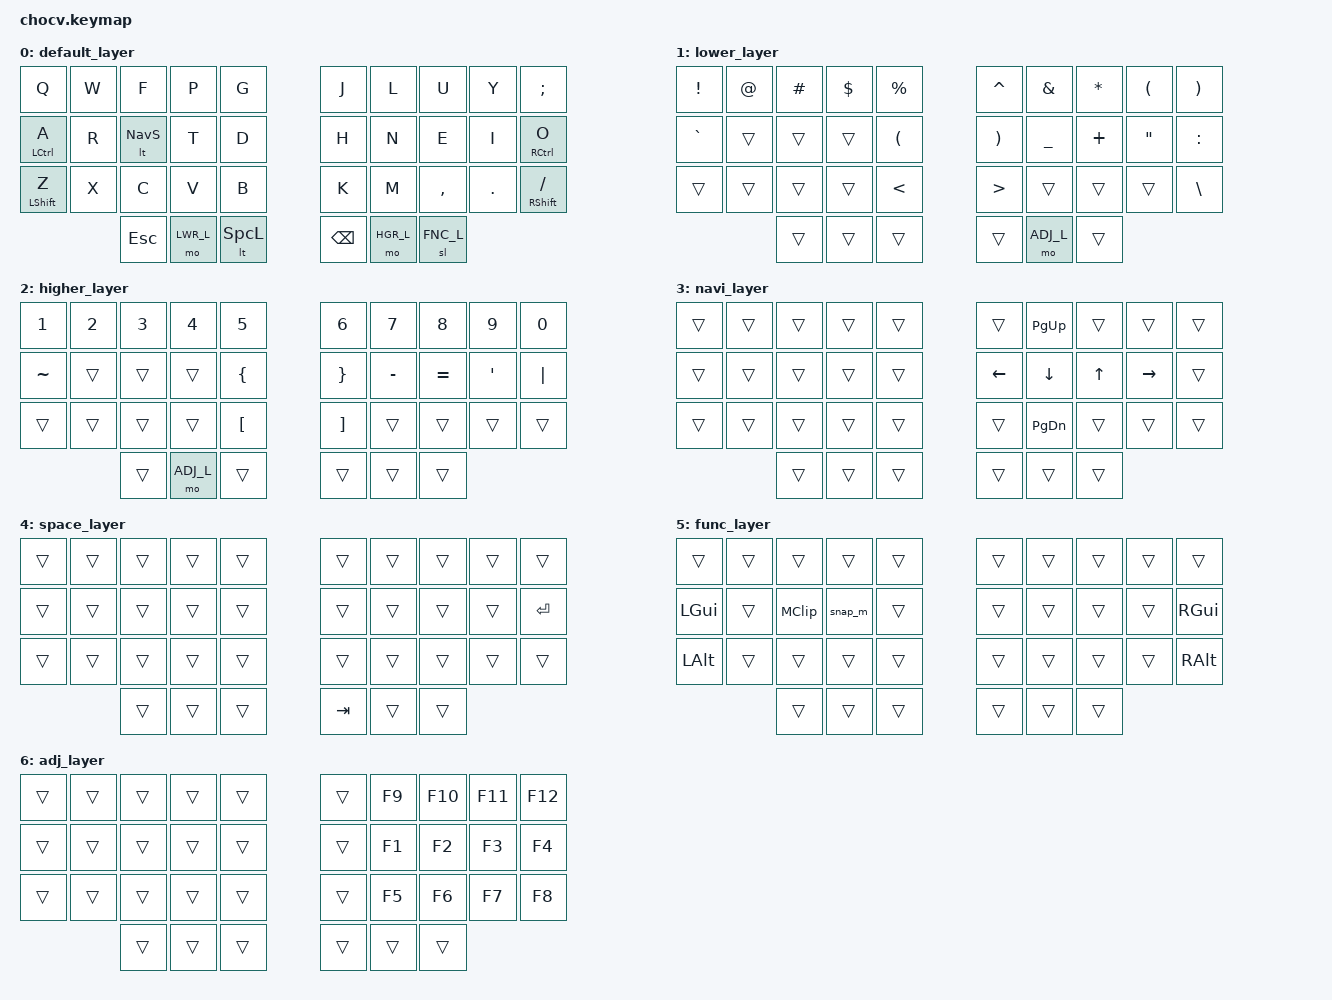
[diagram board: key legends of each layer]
#include <behaviors.dtsi>
#include <dt-bindings/zmk/keys.h>
#include <dt-bindings/zmk/outputs.h>

#define COLEMK_L 0
#define LWR_L    1
#define HGR_L    2
#define NAV_L    3
#define SPC_L    4
#define FNC_L    5
#define ADJ_L    6

#define Undo   LC(Z)
#define Cut    LC(X)
#define Copy   LC(C)
#define Paste  LC(V)
// Windows
#define Clip   LG(LS(S))
#define Wind   LA(PSCRN)
//MacOS
#define MClip  LS(LG(N4))

#define NavS   NAV_L S
#define SpcL   SPC_L SPACE

/ {
    macros {
        snap_m: snap_m {
            label = "ZM_snap_window_mac";
            compatible = "zmk,behavior-macro";
            #binding-cells = <0>;
            bindings
                = <&macro_press &kp LGUI &kp LSHFT &kp N4>
                , <&macro_tap &kp SPACE>
                , <&macro_release &kp LGUI &kp LSHFT &kp N4>
                ;
        };
    };
};

&mt {
	flavor = "tap-preferred";
        tapping_term_ms = <185>;
        retro-tap;
};

&lt {
	flavor = "tap-preferred";
        tapping_term_ms = <185>;
	retro-tap;
};

&sl {
        release-after-ms = <2000>;
};

/ {
        keymap {
                compatible = "zmk,keymap";

                default_layer {
                        bindings = <
&kp Q        &kp W      &kp F     &kp P      &kp G               &kp J      &kp L     &kp U      &kp Y    &kp SEMI   
&mt LCTRL A  &kp R      &lt NavS  &kp T      &kp D               &kp H      &kp N     &kp E      &kp I    &mt RCTRL O      
&mt LSHFT Z  &kp X      &kp C     &kp V      &kp B               &kp K      &kp M     &kp COMMA  &kp DOT  &mt RSHFT SLASH
                        &kp ESC   &mo LWR_L  &lt SpcL            &kp BSPC   &mo HGR_L &sl FNC_L   
                        >;
			
                        sensor-bindings = <&inc_dec_kp C_VOL_UP C_VOL_DN &inc_dec_kp PG_UP PG_DN>;
                };

                lower_layer {
                        bindings = <
&kp EXCL   &kp AT  &kp HASH  &kp DLLR  &kp PRCNT                                  &kp CARET  &kp AMPS   &kp STAR  &kp LPAR  &kp RPAR   
&kp GRAVE  &trans  &trans    &trans    &kp LPAR                                   &kp RPAR   &kp UNDER  &kp PLUS  &kp DQT   &kp COLON  
&trans     &trans  &trans    &trans    &kp LT                                     &kp GT     &trans     &trans    &trans    &kp BSLH   
                   &trans    &trans    &trans                                     &trans     &mo ADJ_L  &trans   
                        >;
			
                        sensor-bindings = <&inc_dec_kp C_VOL_UP C_VOL_DN &inc_dec_kp PG_UP PG_DN>;
                };

                higher_layer {
                        bindings = <
&kp N1     &kp N2  &kp N3  &kp N4     &kp N5                      &kp N6    &kp N7     &kp N8     &kp N9   &kp N0
&kp TILDE  &trans  &trans  &trans     &kp LBRC                    &kp RBRC  &kp MINUS  &kp EQUAL  &kp SQT  &kp PIPE
&trans     &trans  &trans  &trans     &kp LBKT                    &kp RBKT  &trans     &trans     &trans   &trans
                   &trans  &mo ADJ_L  &trans                      &trans    &trans     &trans   
                        >;
			
                        sensor-bindings = <&inc_dec_kp C_VOL_UP C_VOL_DN &inc_dec_kp PG_UP PG_DN>;
                };

                navi_layer {
                        bindings = <
&trans  &trans  &trans  &trans  &trans                             &trans    &kp PG_UP  &trans  &trans     &trans
&trans  &trans  &trans  &trans  &trans                             &kp LEFT  &kp DOWN   &kp UP  &kp RIGHT  &trans
&trans  &trans  &trans  &trans  &trans                             &trans    &kp PG_DN  &trans  &trans     &trans
                &trans  &trans  &trans                             &trans    &trans     &trans   
                        >;
			
                        sensor-bindings = <&inc_dec_kp C_VOL_UP C_VOL_DN &inc_dec_kp PG_UP PG_DN>;
                };

                space_layer {
                        bindings = <
&trans  &trans  &trans  &trans  &trans                             &trans   &trans  &trans  &trans  &trans
&trans  &trans  &trans  &trans  &trans                             &trans   &trans  &trans  &trans  &kp ENTER
&trans  &trans  &trans  &trans  &trans                             &trans   &trans  &trans  &trans  &trans
                &trans  &trans  &trans                             &kp TAB  &trans  &trans   
                        >;
			
                        sensor-bindings = <&inc_dec_kp C_VOL_UP C_VOL_DN &inc_dec_kp PG_UP PG_DN>;
                };

                func_layer {
                        bindings = <
&trans    &trans  &trans    &trans   &trans                       &trans  &trans  &trans  &trans  &trans
&kp LGUI  &trans  &kp MClip &snap_m  &trans                       &trans  &trans  &trans  &trans  &kp RGUI
&kp LALT  &trans  &trans    &trans   &trans                       &trans  &trans  &trans  &trans  &kp RALT
                  &trans    &trans   &trans                       &trans  &trans  &trans   
                        >;
			
                        sensor-bindings = <&inc_dec_kp C_VOL_UP C_VOL_DN &inc_dec_kp PG_UP PG_DN>;
                };

                adj_layer {
                        bindings = <
&trans  &trans  &trans  &trans  &trans                             &trans  &kp F9  &kp F10  &kp F11  &kp F12
&trans  &trans  &trans  &trans  &trans                             &trans  &kp F1  &kp F2   &kp F3   &kp F4
&trans  &trans  &trans  &trans  &trans                             &trans  &kp F5  &kp F6   &kp F7   &kp F8
                &trans  &trans  &trans                             &trans  &trans  &trans   
                        >;
			
                        sensor-bindings = <&inc_dec_kp C_VOL_UP C_VOL_DN &inc_dec_kp PG_UP PG_DN>;
                };
        };
};
